# MCF5441x register map
Vendor: NXP; File version: 1.0
Registers are 32-bit, read-write, reset 0x0 unless marked. A register's access mark holds for its fields unless they carry their own. Offsets are from the block's base; [hi:lo] are bit positions; {n}, {i} and the like mark numbered series; 'fields as' and 'values as' point back to an identical list.

## USBOTG
Base 0xFC0B0000
0x00 ID ro reset 0xE241FA05
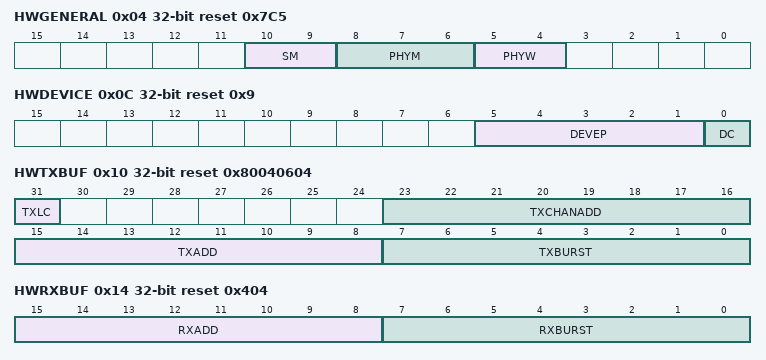
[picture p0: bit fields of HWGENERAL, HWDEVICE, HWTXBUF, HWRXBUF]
0x04 HWGENERAL ro reset 0x7C5
  [10:9] SM, [8:6] PHYM, [5:4] PHYW
0x08 HWHOST ro reset 0x10020001
0x0C HWDEVICE ro reset 0x9
  [5:1] DEVEP, [0] DC
0x10 HWTXBUF ro reset 0x80040604
  [31] TXLC, [23:16] TXCHANADD, [15:8] TXADD, [7:0] TXBURST
0x14 HWRXBUF ro reset 0x404
  [15:8] RXADD, [7:0] RXBURST
0x80 GPTIMER0LD
  [23:0] GPTLD
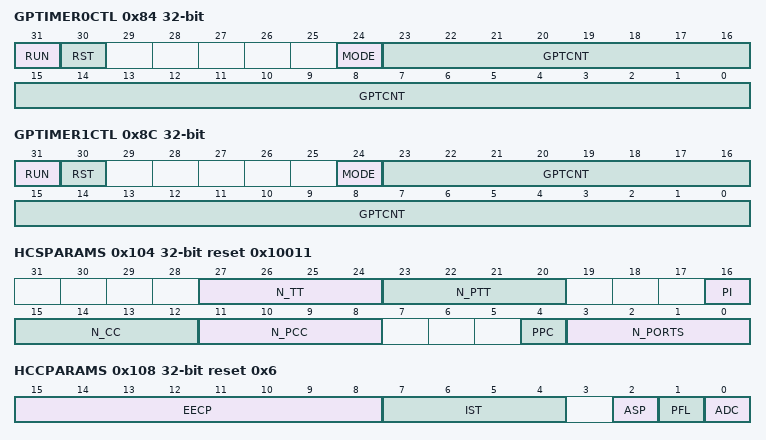
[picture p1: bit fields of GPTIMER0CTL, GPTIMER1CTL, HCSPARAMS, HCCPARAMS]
0x84 GPTIMER0CTL
  [31] RUN
    0=STOP; 1=RUN
  [30] RST
    0=NO_ACTION; 1=LOAD_COUNTER_VALUE
  [24] MODE
    0=ONE_SHOT; 1=REPEAT
  [23:0] GPTCNT
0x88 GPTIMER1LD
  [23:0] GPTLD
0x8C GPTIMER1CTL
  fields as GPTIMER0CTL
0x100 HCIVERSION 16-bit ro reset 0x100
0x103 CAPLENGTH 8-bit ro reset 0x40
0x104 HCSPARAMS ro reset 0x10011
  [27:24] N_TT, [23:20] N_PTT, [16] PI, [15:12] N_CC, [11:8] N_PCC, [4] PPC, [3:0] N_PORTS
0x108 HCCPARAMS ro reset 0x6
  [15:8] EECP
  [7:4] IST
  [2] ASP
    0=NOT_SUPPORTED; 1=SUPPORTED
  [1] PFL
  [0] ADC
0x122 DCIVERSION 16-bit ro reset 0x1
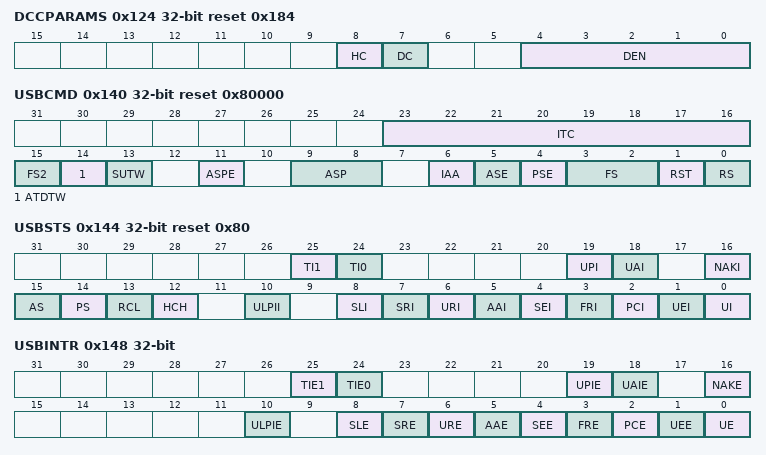
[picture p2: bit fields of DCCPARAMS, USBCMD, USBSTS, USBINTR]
0x124 DCCPARAMS ro reset 0x184
  [8] HC, [7] DC, [4:0] DEN
0x140 USBCMD reset 0x80000
  [23:16] ITC
  [15] FS2
  [14] ATDTW
  [13] SUTW
  [11] ASPE
    0=DISABLED; 1=ENABLED
  [9:8] ASP
  [6] IAA
  [5] ASE
  [4] PSE
  [3:2] FS
  [1] RST
  [0] RS
0x144 USBSTS reset 0x80
  [25] TI1 write-1-clears
    0=NO_INTERRUPT; 1=INTERRUPT_OCCURRED
  [24] TI0 write-1-clears
    0=NO_INTERRUPT; 1=INTERRUPT_OCCURRED
  [19] UPI
  [18] UAI
  [16] NAKI
  [15] AS
    0=DISABLED; 1=ENABLED
  [14] PS
    0=DISABLED; 1=ENABLED
  [13] RCL
    0=NON_EMPTY_ASYNCHRONOUS_SCHEDULE; 1=EMPTY_ASYNCHRONOUS_SCHEDULE
  [12] HCH
    0=RUNNING; 1=HALTED
  [10] ULPII
  [8] SLI write-1-clears
    0=ACTIVE; 1=SUSPENDED
  [7] SRI write-1-clears
  [6] URI write-1-clears
    0=NO_RESET_RECEIVED; 1=RESET_RECEIVED
  [5] AAI write-1-clears
    0=NO_ASYNC_ADVANCE_INTERRUPT; 1=ASYNC_ADVANCE_INTERRUPT
  [4] SEI write-1-clears
    0=NORMAL_OPERATION; 1=ERROR
  [3] FRI write-1-clears
  [2] PCI write-1-clears
  [1] UEI write-1-clears
    0=NO_ERROR; 1=ERROR_DETECTED
  [0] UI write-1-clears
0x148 USBINTR
  [25] TIE1
    0=DISABLED; 1=ENABLED
  [24] TIE0
    0=DISABLED; 1=ENABLED
  [19] UPIE
  [18] UAIE
  [16] NAKE
    0=DISABLED; 1=ENABLED
  [10] ULPIE
  [8] SLE
    0=DISABLED; 1=ENABLED
  [7] SRE
    0=DISABLED; 1=ENABLED
  [6] URE
    0=DISABLED; 1=ENABLED
  [5] AAE
    0=DISABLED; 1=ENABLED
  [4] SEE
    0=DISABLED; 1=ENABLED
  [3] FRE
    0=DISABLED; 1=ENABLED
  [2] PCE
    0=DISABLED; 1=ENABLED
  [1] UEE
    0=DISABLED; 1=ENABLED
  [0] UE
    0=DISABLED; 1=ENABLED
0x14C FRINDEX
  [13:0] FRINDEX
0x154 DEVICEADDR
  [31:25] USBADR
0x154 PERIODICLISTBASE
  [31:12] PERBASE
0x158 ASYNCLISTADDR
  [31:5] ASYBASE
0x158 EPLISTADDR
  [31:11] EPBASE
0x15C TTCTRL
  [30:24] TTHA
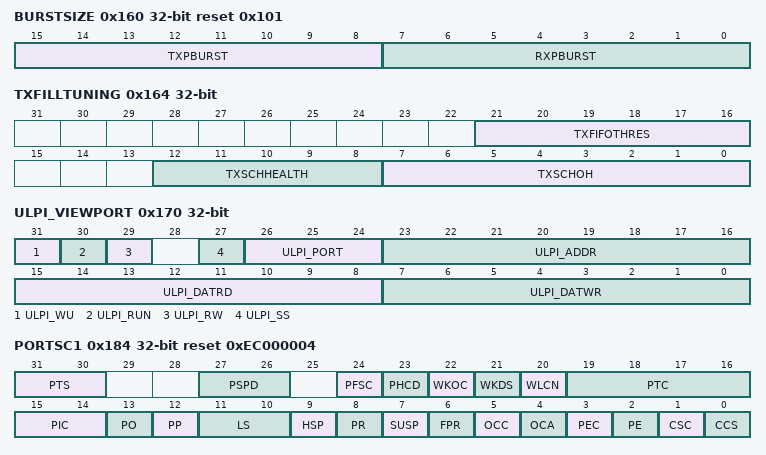
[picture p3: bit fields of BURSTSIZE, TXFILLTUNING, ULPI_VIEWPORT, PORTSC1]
0x160 BURSTSIZE reset 0x101
  [15:8] TXPBURST, [7:0] RXPBURST
0x164 TXFILLTUNING
  [21:16] TXFIFOTHRES, [12:8] TXSCHHEALTH, [7:0] TXSCHOH
0x170 ULPI_VIEWPORT
  [31] ULPI_WU
  [30] ULPI_RUN
  [29] ULPI_RW
    0=READ; 1=WRITE
  [27] ULPI_SS
  [26:24] ULPI_PORT
  [23:16] ULPI_ADDR
  [15:8] ULPI_DATRD
  [7:0] ULPI_DATWR
0x180 CONFIGFLAG ro reset 0x1
0x184 PORTSC1 reset 0xEC000004
  [31:30] PTS
  [27:26] PSPD
    0=FULL_SPEED; 1=LOW_SPEED; 2=HIGH_SPEED; 3=UNDEFINED
  [24] PFSC
  [23] PHCD
  [22] WKOC
  [21] WKDS
  [20] WLCN
  [19:16] PTC
    0=NOT_ENABLED; 1=J_STATE; 2=K_STATE; 3=SEQ_NAK; 4=PACKET; 5=FORCE_ENABLE_HS; 6=FORCE_ENABLE_FS; 7=FORCE_ENABLE_LS
  [15:14] PIC
    0=OFF; 1=AMBER; 2=GREEN; 3=UNDEFINED
  [13] PO
  [12] PP
  [11:10] LS
    0=SE0; 1=J_STATE; 2=K_STATE; 3=UNDEFINED
  [9] HSP
    0=FS_OR_LS; 1=HS
  [8] PR
    0=NOT_IN_RESET; 1=IN_RESET
  [7] SUSP
  [6] FPR
  [5] OCC
    0=NO_OVER_CURRENT; 1=OVER_CURRENT_DETECT
  [4] OCA
  [3] PEC
    0=NO_CHANGE; 1=PORT_DISABLED
  [2] PE
  [1] CSC
    0=NO_CHANGE; 1=CONNECT_STATUS_HAS_CHANGED
  [0] CCS
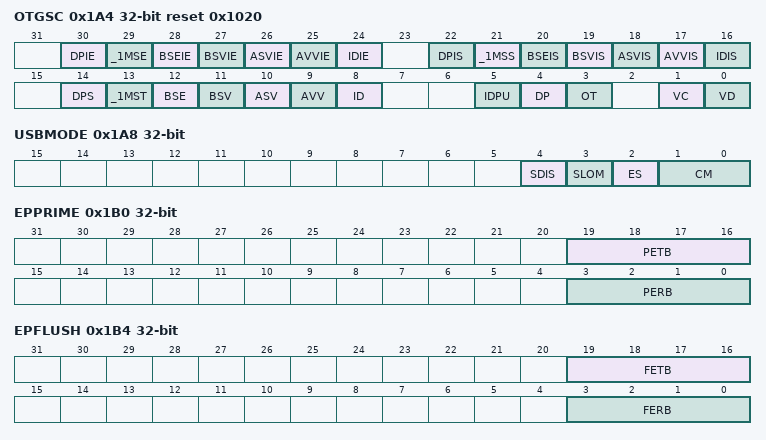
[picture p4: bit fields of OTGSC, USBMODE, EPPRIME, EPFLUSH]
0x1A4 OTGSC reset 0x1020
  [30] DPIE
    0=DISABLE; 1=ENABLE
  [29] _1MSE
  [28] BSEIE
    0=DISABLE; 1=ENABLE
  [27] BSVIE
    0=DISABLE; 1=ENABLE
  [26] ASVIE
    0=DISABLE; 1=ENABLE
  [25] AVVIE
    0=DISABLE; 1=ENABLE
  [24] IDIE
    0=DISABLE; 1=ENABLE
  [22] DPIS write-1-clears
  [21] _1MSS write-1-clears
  [20] BSEIS write-1-clears
  [19] BSVIS write-1-clears
  [18] ASVIS write-1-clears
  [17] AVVIS write-1-clears
  [16] IDIS write-1-clears
  [14] DPS
    0=NO_PULSING_ON_PORT; 1=PULSING_DETECTED_ON_PORT
  [13] _1MST
  [12] BSE
  [11] BSV
  [10] ASV
  [9] AVV
  [8] ID
    0=A_DEVICE; 1=B_DEVICE
  [5] IDPU
  [4] DP
  [3] OT
    0=DISABLE_PULL_DOWN_ON_DM; 1=ENABLE_PULL_DOWN_ON_DM
  [1] VC
  [0] VD
0x1A8 USBMODE
  [4] SDIS
    0=INACTIVE; 1=ACTIVE
  [3] SLOM
  [2] ES
  [1:0] CM
0x1AC EPSETUPSR
  [3:0] EPSETUPSTAT write-1-clears
0x1B0 EPPRIME
  [19:16] PETB, [3:0] PERB
0x1B4 EPFLUSH
  [19:16] FETB, [3:0] FERB
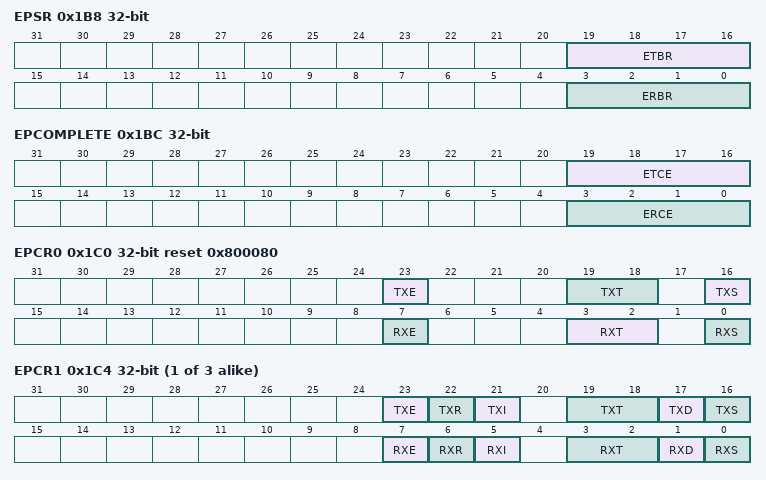
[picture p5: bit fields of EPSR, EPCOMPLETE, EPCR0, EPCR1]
0x1B8 EPSR ro
  [19:16] ETBR, [3:0] ERBR
0x1BC EPCOMPLETE
  [19:16] ETCE write-1-clears, [3:0] ERCE write-1-clears
0x1C0 EPCR0 reset 0x800080
  [23] TXE
  [19:18] TXT
  [16] TXS
    0=OK; 1=STALLED
  [7] RXE
  [3:2] RXT
  [0] RXS
    0=OK; 1=STALLED
{0x1C0+4i} EPCR{i} (i=1..3)
  [23] TXE
    0=DISABLED; 1=ENABLED
  [22] TXR
  [21] TXI
    0=ENABLED; 1=DISABLED
  [19:18] TXT
    0=CONTROL; 1=ISOCHRONOUS; 2=BULK; 3=INTERRUPT
  [17] TXD
  [16] TXS
    0=OK; 1=STALLED
  [7] RXE
    0=DISABLED; 1=ENABLED
  [6] RXR
  [5] RXI
    0=ENABLED; 1=DISABLED
  [3:2] RXT
    0=CONTROL; 1=ISOCHRONOUS; 2=BULK; 3=INTERRUPT
  [1] RXD
  [0] RXS
    0=OK; 1=STALLED
